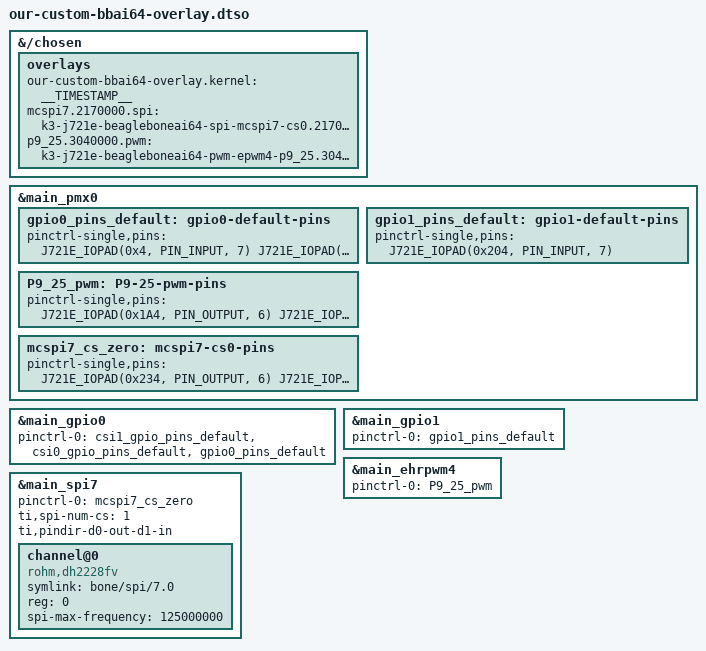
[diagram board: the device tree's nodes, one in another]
// SPDX-License-Identifier: GPL-2.0-only OR MIT
/*
 * DT Overlay
 *
 * Copyright (C) 2023 Texas Instruments Incorporated - https://www.ti.com/
 *
 */

/dts-v1/;
/plugin/;

#include <dt-bindings/gpio/gpio.h>
#include "ti/k3-pinctrl.h"

/*
 * Helper to show loaded overlays under: /proc/device-tree/chosen/overlays/
*/
&{/chosen} {
        overlays {
                our-custom-bbai64-overlay.kernel = __TIMESTAMP__;
                mcspi7.2170000.spi = "k3-j721e-beagleboneai64-spi-mcspi7-cs0.2170000";
                p9_25.3040000.pwm = "k3-j721e-beagleboneai64-pwm-epwm4-p9_25.3040000.1.P9_25";
        };
};

&main_pmx0 {
	gpio0_pins_default: gpio0-default-pins {
		pinctrl-single,pins = <
			J721E_IOPAD(0x4, PIN_INPUT, 7) /* P9_11 (AC23) PRG1_PRU0_GPO0.GPIO0_1 */
			J721E_IOPAD(0x8, PIN_INPUT, 7) /* P9_13 (AG22) PRG1_PRU0_GPO1.GPIO0_2 */
			J721E_IOPAD(0xc, PIN_INPUT, 7) /* P8_17 (AF22) PRG1_PRU0_GPO2.GPIO0_3 */
			J721E_IOPAD(0x10, PIN_INPUT, 7) /* P8_18 (AJ23) PRG1_PRU0_GPO3.GPIO0_4 */
			J721E_IOPAD(0x14, PIN_INPUT, 7) /* P8_22 (AH23) PRG1_PRU0_GPO4.GPIO0_5 */
			J721E_IOPAD(0x18, PIN_INPUT, 7) /* P8_24 (AD20) PRG1_PRU0_GPO5.GPIO0_6 */
			J721E_IOPAD(0x1c, PIN_INPUT, 7) /* P8_34 (AD22) PRG1_PRU0_GPO6.GPIO0_7 */
			J721E_IOPAD(0x20, PIN_INPUT, 7) /* P8_36 (AE20) PRG1_PRU0_GPO7.GPIO0_8 */
			J721E_IOPAD(0x24, PIN_INPUT, 7) /* P8_38b (AJ20) PRG1_PRU0_GPO8.GPIO0_9 */
			J721E_IOPAD(0x28, PIN_INPUT, 7) /* P9_23 (AG20) PRG1_PRU0_GPO9.GPIO0_10 */
			J721E_IOPAD(0x2c, PIN_INPUT, 7) /* P8_37b (AD21) PRG1_PRU0_GPO10.GPIO0_11 */
			/* J721E_IOPAD(0x30, PIN_INPUT, 7) */ /* P9_26b (AF24) PRG1_PRU0_GPO11.GPIO0_12 */
			/* J721E_IOPAD(0x34, PIN_INPUT, 7) */ /* P9_24b (AJ24) PRG1_PRU0_GPO12.GPIO0_13 */
			J721E_IOPAD(0x38, PIN_INPUT, 7) /* P8_08 (AG24) PRG1_PRU0_GPO13.GPIO0_14 */
			J721E_IOPAD(0x3c, PIN_INPUT, 7) /* P8_07 (AD24) PRG1_PRU0_GPO14.GPIO0_15 */
			J721E_IOPAD(0x40, PIN_INPUT, 7) /* P8_10 (AC24) PRG1_PRU0_GPO15.GPIO0_16 */
			J721E_IOPAD(0x44, PIN_INPUT, 7) /* P8_09 (AE24) PRG1_PRU0_GPO16.GPIO0_17 */
			J721E_IOPAD(0x4c, PIN_INPUT, 7) /* P9_42b (AJ21) PRG1_PRU0_GPO17.GPIO0_18 */
			J721E_IOPAD(0x54, PIN_INPUT, 7) /* P8_03 (AH21) PRG1_PRU0_GPO19.GPIO0_20 */
            J721E_IOPAD(0x64, PIN_INPUT, 7) /* P8_35a (AD23) PRG1_PRU1_GPO3.GPIO0_24 */
			J721E_IOPAD(0x68, PIN_INPUT, 7) /* P8_33a (AH24) PRG1_PRU1_GPO4.GPIO0_25 */
			J721E_IOPAD(0x6c, PIN_INPUT, 7) /* P8_32a (AG21) PRG1_PRU1_GPO5.GPIO0_26 */
			/* J721E_IOPAD(0x74, PIN_INPUT, 7) */ /* P9_17a (AC21) PRG1_PRU1_GPO7.GPIO0_28 */
			J721E_IOPAD(0x7c, PIN_INPUT, 7) /* P8_21 (AF21) PRG1_PRU1_GPO9.GPIO0_30 */
			J721E_IOPAD(0x80, PIN_INPUT, 7) /* P8_23 (AB23) PRG1_PRU1_GPO10.GPIO0_31 */
			J721E_IOPAD(0x84, PIN_INPUT, 7) /* P8_31a (AJ25) PRG1_PRU1_GPO11.GPIO0_32 */
			J721E_IOPAD(0x88, PIN_INPUT, 7) /* P8_05 (AH25) PRG1_PRU1_GPO12.GPIO0_33 */
			J721E_IOPAD(0x8c, PIN_INPUT, 7) /* P8_06 (AG25) PRG1_PRU1_GPO13.GPIO0_34 */
			J721E_IOPAD(0x90, PIN_INPUT, 7) /* P8_25 (AH26) PRG1_PRU1_GPO14.GPIO0_35 */
			J721E_IOPAD(0x9c, PIN_INPUT, 7) /* P9_22a (AC22) PRG1_PRU1_GPO17.GPIO0_38 */
			J721E_IOPAD(0xa0, PIN_INPUT, 7) /* P9_21a (AJ22) PRG1_PRU1_GPO18.GPIO0_39 */
			/* J721E_IOPAD(0xa4, PIN_INPUT, 7) */ /* P9_18a (AH22) PRG1_PRU1_GPO19.GPIO0_40 */
			/* J721E_IOPAD(0xb0, PIN_INPUT, 7) */ /* P9_28b (AF28) PRG0_PRU0_GPO0.GPIO0_43 */
			/* J721E_IOPAD(0xb4, PIN_INPUT, 7) */ /* P9_30b (AE28) PRG0_PRU0_GPO1.GPIO0_44 */
			J721E_IOPAD(0xb8, PIN_INPUT, 7) /* P9_12 (AE27) PRG0_PRU0_GPO2.GPIO0_45 */
			J721E_IOPAD(0xbc, PIN_INPUT, 7) /* P9_27a (AD26) PRG0_PRU0_GPO3.GPIO0_46 */
			J721E_IOPAD(0xc0, PIN_INPUT, 7) /* P9_15 (AD25) PRG0_PRU0_GPO4.GPIO0_47 */
			J721E_IOPAD(0xc4, PIN_INPUT, 7) /* P8_04 (AC29) PRG0_PRU0_GPO5.GPIO0_48 */
			J721E_IOPAD(0xcc, PIN_INPUT, 7) /* P9_33b (AC28) PRG0_PRU0_GPO7.GPIO0_50 */
			J721E_IOPAD(0xd0, PIN_INPUT, 7) /* P8_26 (AC27) PRG0_PRU0_GPO8.GPIO0_51 */
			/* J721E_IOPAD(0xd4, PIN_INPUT, 7) */ /* P9_31b (AB26) PRG0_PRU0_GPO9.GPIO0_52 */
			/* J721E_IOPAD(0xd8, PIN_INPUT, 7) */ /* P9_29b (AB25) PRG0_PRU0_GPO10.GPIO0_53 */
			J721E_IOPAD(0xdc, PIN_INPUT, 7) /* P9_39b (AJ28) PRG0_PRU0_GPO11.GPIO0_54 */
			J721E_IOPAD(0xe0, PIN_INPUT, 7) /* P9_35b (AH27) PRG0_PRU0_GPO12.GPIO0_55 */
			J721E_IOPAD(0xe4, PIN_INPUT, 7) /* P9_36b (AH29) PRG0_PRU0_GPO13.GPIO0_56 */
			J721E_IOPAD(0xe8, PIN_INPUT, 7) /* P9_37b (AG28) PRG0_PRU0_GPO14.GPIO0_57 */
			J721E_IOPAD(0xec, PIN_INPUT, 7) /* P9_38b (AG27) PRG0_PRU0_GPO15.GPIO0_58 */
			J721E_IOPAD(0xf0, PIN_INPUT, 7) /* P8_12 (AH28) PRG0_PRU0_GPO16.GPIO0_59 */
			J721E_IOPAD(0xf4, PIN_INPUT, 7) /* P8_11 (AB24) PRG0_PRU0_GPO17.GPIO0_60 */
			J721E_IOPAD(0xf8, PIN_INPUT, 7) /* P8_15 (AB29) PRG0_PRU0_GPO18.GPIO0_61 */
			J721E_IOPAD(0xfc, PIN_INPUT, 7) /* P8_16 (AB28) PRG0_PRU0_GPO19.GPIO0_62 */
			J721E_IOPAD(0x100, PIN_INPUT, 7) /* P8_31b (AE29) PRG0_PRU1_GPO0.GPIO0_63 */
			J721E_IOPAD(0x104, PIN_INPUT, 7) /* P8_32b (AD28) PRG0_PRU1_GPO1.GPIO0_64 */
			J721E_IOPAD(0x108, PIN_INPUT, 7) /* P8_43 (AD27) PRG0_PRU1_GPO2.GPIO0_65 */
			J721E_IOPAD(0x10c, PIN_INPUT, 7) /* P8_44 (AC25) PRG0_PRU1_GPO3.GPIO0_66 */
			J721E_IOPAD(0x110, PIN_INPUT, 7) /* P8_41 (AD29) PRG0_PRU1_GPO4.GPIO0_67 */
			J721E_IOPAD(0x114, PIN_INPUT, 7) /* P8_42 (AB27) PRG0_PRU1_GPO5.GPIO0_68 */
			J721E_IOPAD(0x118, PIN_INPUT, 7) /* P8_39 (AC26) PRG0_PRU1_GPO6.GPIO0_69 */
			J721E_IOPAD(0x11c, PIN_INPUT, 7) /* P8_40 (AA24) PRG0_PRU1_GPO7.GPIO0_70 */
			J721E_IOPAD(0x120, PIN_INPUT, 7) /* P8_27 (AA28) PRG0_PRU1_GPO8.GPIO0_71 */
			J721E_IOPAD(0x124, PIN_INPUT, 7) /* P8_28 (Y24) PRG0_PRU1_GPO9.GPIO0_72 */
			J721E_IOPAD(0x128, PIN_INPUT, 7) /* P8_29 (AA25) PRG0_PRU1_GPO10.GPIO0_73 */
			J721E_IOPAD(0x12c, PIN_INPUT, 7) /* P8_30 (AG26) PRG0_PRU1_GPO11.GPIO0_74 */
			J721E_IOPAD(0x130, PIN_INPUT, 7) /* P8_14 (AF27) PRG0_PRU1_GPO12.GPIO0_75 */
			J721E_IOPAD(0x134, PIN_INPUT, 7) /* P8_20 (AF26) PRG0_PRU1_GPO13.GPIO0_76 */
			/* J721E_IOPAD(0x138, PIN_INPUT, 7) */ /* P9_20b (AE25) PRG0_PRU1_GPO14.GPIO0_77 */
			/* J721E_IOPAD(0x13c, PIN_INPUT, 7) */ /* P9_19b (AF29) PRG0_PRU1_GPO15.GPIO0_78 */
			J721E_IOPAD(0x140, PIN_INPUT, 7) /* P8_45 (AG29) PRG0_PRU1_GPO16.GPIO0_79 */
			J721E_IOPAD(0x144, PIN_INPUT, 7) /* P8_46 (Y25) PRG0_PRU1_GPO17.GPIO0_80 */
            J721E_IOPAD(0x148, PIN_INPUT, 7) /* P9_40b(AA26) PRG0_PRU1_GPO18.GPIO0_81 */
			J721E_IOPAD(0x164, PIN_INPUT, 7) /* P8_19 (V29) RGMII5_TD2.GPIO0_88 */
			J721E_IOPAD(0x168, PIN_INPUT, 7) /* P8_13 (V27) RGMII5_TD1.GPIO0_89 */
			J721E_IOPAD(0x16c, PIN_INPUT, 7) /* P9_21b (U28) RGMII5_TD0.GPIO0_90 */
			J721E_IOPAD(0x170, PIN_INPUT, 7) /* P9_22b (U29) RGMII5_TXC.GPIO0_91 */
			J721E_IOPAD(0x178, PIN_INPUT, 7) /* P9_14 (U27) RGMII5_RD3.GPIO0_93 */
			J721E_IOPAD(0x17c, PIN_INPUT, 7) /* P9_16 (U24) RGMII5_RD2.GPIO0_94 */
			/* J721E_IOPAD(0x1a4, PIN_INPUT, 7) */ /* P9_25b (W26) RGMII6_RXC.GPIO0_104 */
			J721E_IOPAD(0x1a8, PIN_INPUT, 7) /* P8_38a (Y29) RGMII6_RD3.GPIO0_105 */
			J721E_IOPAD(0x1ac, PIN_INPUT, 7) /* P8_37a (Y27) RGMII6_RD2.GPIO0_106 */
			J721E_IOPAD(0x1c0, PIN_INPUT, 7) /* P8_33b (AA2) SPI0_CS0.GPIO0_111 */
			/* J721E_IOPAD(0x1d0, PIN_INPUT, 7) */ /* P9_17b (AA3) SPI0_D1.GPIO0_115 */
			J721E_IOPAD(0x1d4, PIN_INPUT, 7) /* P8_35b (Y3) SPI1_CS0.GPIO0_116 */
			/* J721E_IOPAD(0x1dc, PIN_INPUT, 7) */ /* P9_26a (Y1) SPI1_CLK.GPIO0_118 */
			/* J721E_IOPAD(0x1e0, PIN_INPUT, 7) */ /* P9_24a (Y5) SPI1_D0.GPIO0_119 */
			/* J721E_IOPAD(0x1e4, PIN_INPUT, 7) */ /* P9_18b (Y2) SPI1_D1.GPIO0_120 */
			J721E_IOPAD(0x1f0, PIN_INPUT, 7) /* P9_42a (AC2) UART0_CTSn.GPIO0_123 */
			J721E_IOPAD(0x1f4, PIN_INPUT, 7) /* P9_27b (AB1) UART0_RTSn.GPIO0_124 */
			/* J721E_IOPAD(0x200, PIN_INPUT, 7) */ /* P9_25a (AC4) UART1_CTSn.GPIO0_127 */
		>;
	};

	gpio1_pins_default: gpio1-default-pins {
		pinctrl-single,pins = <
			J721E_IOPAD(0x204, PIN_INPUT, 7) /* P9_41 (AD5) UART1_RTSn.GPIO1_0 */
			/* J721E_IOPAD(0x208, PIN_INPUT, 7) */ /* P9_19a (W5) MCAN0_RX.GPIO1_1 */
			/* J721E_IOPAD(0x20c, PIN_INPUT, 7) */ /* P9_20a (W6) MCAN0_TX.GPIO1_2 */
			/* J721E_IOPAD(0x230, PIN_INPUT, 7) */ /* P9_28a (U2) ECAP0_IN_APWM_OUT.GPIO1_11 */
            /* J721E_IOPAD(0x234, PIN_INPUT, 7) */ /* P9_31a (U3) EXT_REFCLK1.GPIO1_12 */
			/* J721E_IOPAD(0x238, PIN_INPUT, 7) */ /* P9_30a (V6) TIMER_IO0.GPIO1_13 */
			/* J721E_IOPAD(0x23c, PIN_INPUT, 7) */ /* P9_29a (V5) TIMER_IO1.GPIO1_14 */
		>;
	};
};

&main_gpio0 {
	pinctrl-names = "default";
	pinctrl-0 = <&csi1_gpio_pins_default>, <&csi0_gpio_pins_default>, <&gpio0_pins_default>;
	status = "okay";
};

&main_gpio1 {
	pinctrl-names = "default";
	pinctrl-0 = <&gpio1_pins_default>;
	status = "okay";
};


/* Taken from https://git.beagleboard.org/beagleboard/BeagleBoard-DeviceTrees/-/blob/eeb6e572cff523da1dcaa4dfc11f580b66155b5f/src/arm64/overlays/k3-j721e-beagleboneai64-pwm-epwm4-p9_25.dtso */
&main_pmx0 {
	P9_25_pwm: P9-25-pwm-pins {
		pinctrl-single,pins = <
			J721E_IOPAD(0x1A4, PIN_OUTPUT, 6) /* (W26) RGMII6_RXC.EHRPWM4_B */
			J721E_IOPAD(0x200, PIN_DISABLE, 7) /* (AC4) UART1_CTSn.GPIO0_127 */
		>;
	};
};

&main_ehrpwm4 {
	pinctrl-names = "default";
	pinctrl-0 = <&P9_25_pwm>;
	status = "okay";
};

/* Taken from https://git.beagleboard.org/beagleboard/BeagleBoard-DeviceTrees/-/blob/3d2ad1c69b99c5a6b52bcd35e404397fabf5dbc6/src/arm64/overlays/k3-j721e-beagleboneai64-spi-mcspi7-cs0.dtso */
&main_pmx0 {
	mcspi7_cs_zero: mcspi7-cs0-pins {
		pinctrl-single,pins = <
			J721E_IOPAD(0x234, PIN_OUTPUT, 6) /* (U3) EXT_REFCLK1.SPI7_CLK P9_31a*/
			J721E_IOPAD(0xD4, PIN_DISABLE, 7) /* (AB26) disable p9_31b */
			J721E_IOPAD(0x230, PIN_OUTPUT, 6) /* (U2) ECAP0_IN_APWM_OUT.SPI7_CS0 P9_28a */
			J721E_IOPAD(0xB0, PIN_DISABLE, 7) /* (AF28) disable p9_28b */
			J721E_IOPAD(0x238, PIN_OUTPUT, 6) /* (V6) TIMER_IO0.SPI7_D0 MOSI P9_30a */
			J721E_IOPAD(0xB4, PIN_DISABLE, 7) /* (AE28) disable P9_30b */
			J721E_IOPAD(0x23c, PIN_INPUT, 6) /* (V5) TIMER_IO1.SPI7_D1 MISO P9_29a */
			J721E_IOPAD(0xD8, PIN_DISABLE, 7) /* (AB25) disable p9_29b */
		>;
	};
};

&main_spi7 {
    #address-cells = <1>;
    #size-cells = <0>;
    pinctrl-names = "default";
    pinctrl-0 = <&mcspi7_cs_zero>;
    ti,spi-num-cs = <1>;
    ti,pindir-d0-out-d1-in;
    status = "okay";

	/* THIS IS FOR SPIDEV, to see device at /dev/bone/spi, first run `sudo modprobe spidev` */
	/* When controlling SPI from outside linux, you may want to delete this spidev stuff */
    channel@0 {
        symlink = "bone/spi/7.0";
        compatible = "rohm,dh2228fv";
        reg = <0>; /* CE0 */
        spi-max-frequency = <125000000>;
    };
};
